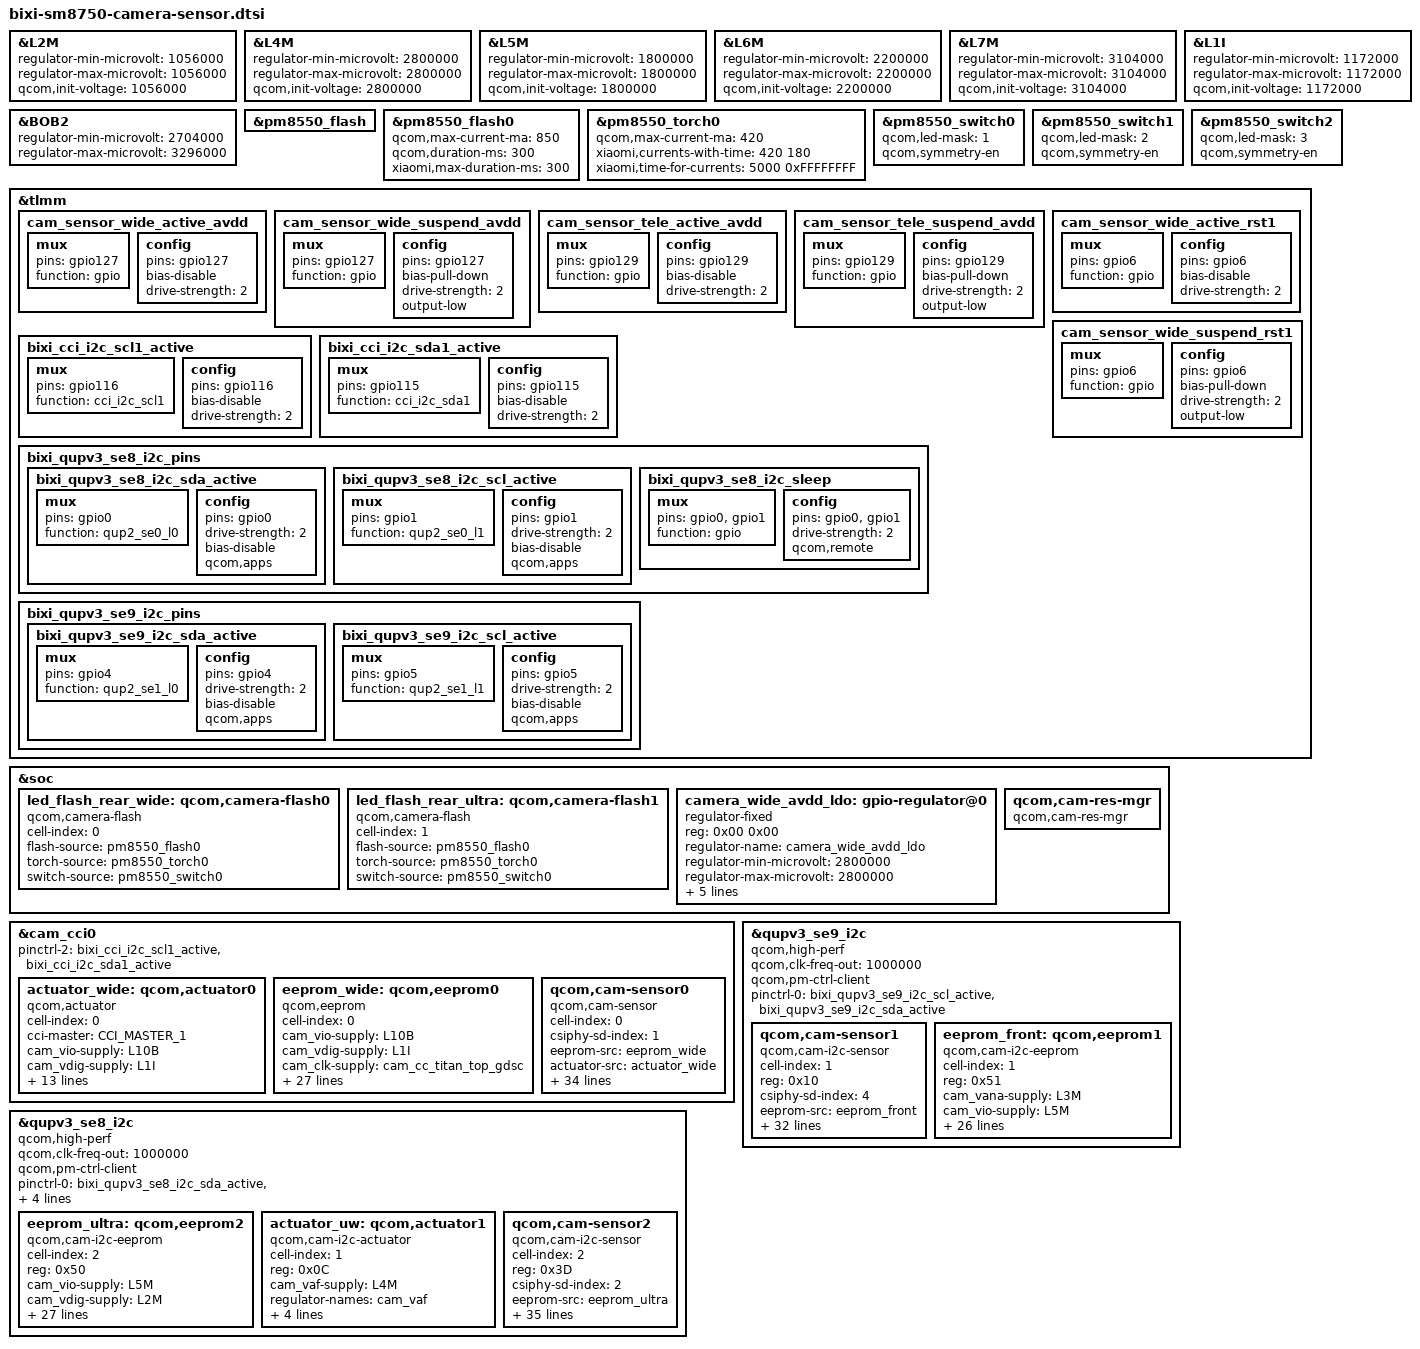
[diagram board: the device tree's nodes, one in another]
#include <dt-bindings/msm-camera.h>

&L2M {
	regulator-min-microvolt = <1056000>;
	regulator-max-microvolt = <1056000>;
	qcom,init-voltage = <1056000>;
};

&L4M {
	regulator-min-microvolt = <2800000>;
	regulator-max-microvolt = <2800000>;
	qcom,init-voltage = <2800000>;
};

&L5M {
	regulator-min-microvolt = <1800000>;
	regulator-max-microvolt = <1800000>;
	qcom,init-voltage = <1800000>;
};

&L6M {
	regulator-min-microvolt = <2200000>;
	regulator-max-microvolt = <2200000>;
	qcom,init-voltage = <2200000>;
};

&L7M {
	regulator-min-microvolt = <3104000>;
	regulator-max-microvolt = <3104000>;
	qcom,init-voltage = <3104000>;
};

&L1I {
	regulator-min-microvolt = <1172000>;
	regulator-max-microvolt = <1172000>;
	qcom,init-voltage = <1172000>;
};

&BOB2 {
	regulator-min-microvolt = <2704000>;
	regulator-max-microvolt = <3296000>;
};

&pm8550_flash {
	status = "ok";
};


&pm8550_flash0 {
	qcom,max-current-ma = <850>;
	qcom,duration-ms = <300>;
	xiaomi,max-duration-ms = <300>;
};

&pm8550_torch0{
	qcom,max-current-ma = <420>;
	xiaomi,currents-with-time = <420 180>;
	xiaomi,time-for-currents = <5000 0xFFFFFFFF>;  /* 0xFFFFFFFF means flash always on*/
};

&pm8550_switch0 {
	qcom,led-mask = <1>;
	qcom,symmetry-en;
};

&pm8550_switch1 {
	qcom,led-mask = <2>;
	qcom,symmetry-en;
};

&pm8550_switch2 {
	qcom,led-mask = <3>;
	qcom,symmetry-en;
};

&tlmm {
//wide avdd
	cam_sensor_wide_active_avdd: cam_sensor_wide_active_avdd {
		mux {
			pins = "gpio127";
			function = "gpio";
		};
		config {
			pins = "gpio127";
			bias-disable; /* No PULL */
			drive-strength = <2>; /* 2 MA */
		};
	};
	cam_sensor_wide_suspend_avdd: cam_sensor_wide_suspend_avdd {
		mux {
			pins = "gpio127";
			function = "gpio";
		};
		config {
			pins = "gpio127";
			bias-pull-down; /* PULL DOWN */
			drive-strength = <2>; /* 2 MA */
			output-low;
		};
	};

//tele avdd
	cam_sensor_tele_active_avdd: cam_sensor_tele_active_avdd {
		mux {
			pins = "gpio129";
			function = "gpio";
		};
		config {
			pins = "gpio129";
			bias-disable; /* No PULL */
			drive-strength = <2>; /* 2 MA */
		};
	};
	cam_sensor_tele_suspend_avdd: cam_sensor_tele_suspend_avdd {
		mux {
			pins = "gpio129";
			function = "gpio";
		};
		config {
			pins = "gpio129";
			bias-pull-down; /* PULL DOWN */
			drive-strength = <2>; /* 2 MA */
			output-low;
		};
	};

//Wide reset
	cam_sensor_wide_active_rst1: cam_sensor_wide_active_rst1 {
		mux {
			pins = "gpio6";
			function = "gpio";
		};

		config {
			pins = "gpio6";
			bias-disable; /* No PULL */
			drive-strength = <2>; /* 2 MA */
		};
	};

	cam_sensor_wide_suspend_rst1: cam_sensor_wide_suspend_rst1 {
		mux {
			pins = "gpio6";
			function = "gpio";
		};

		config {
			pins = "gpio6";
			bias-pull-down; /* PULL DOWN */
			drive-strength = <2>; /* 2 MA */
			output-low;
		};
	};

	bixi_cci_i2c_scl1_active: bixi_cci_i2c_scl1_active {
		mux {
			/* CLK, DATA */
			pins = "gpio116";
			function = "cci_i2c_scl1";
		};

		config {
			pins = "gpio116";
			bias-disable; /* NO PULL */
			drive-strength = <2>; /* 2 MA */
		};
	};

	bixi_cci_i2c_sda1_active: bixi_cci_i2c_sda1_active {
		mux {
			/* CLK, DATA */
			pins = "gpio115";
			function = "cci_i2c_sda1";
		};

		config {
			pins = "gpio115";
			bias-disable; /* NO PULL */
			drive-strength = <2>; /* 2 MA */
		};
	};

	bixi_qupv3_se8_i2c_pins: bixi_qupv3_se8_i2c_pins {
		bixi_qupv3_se8_i2c_sda_active: bixi_qupv3_se8_i2c_sda_active {
			mux {
				pins = "gpio0";
				function = "qup2_se0_l0";
			};

			config {
				pins = "gpio0";
				drive-strength = <2>;
				bias-disable;
				qcom,apps;
			};
		};

		bixi_qupv3_se8_i2c_scl_active: bixi_qupv3_se8_i2c_scl_active {
			mux {
				pins = "gpio1";
				function = "qup2_se0_l1";
			};

			config {
				pins = "gpio1";
				drive-strength = <2>;
				bias-disable;
				qcom,apps;
			};
		};

		bixi_qupv3_se8_i2c_sleep: bixi_qupv3_se8_i2c_sleep {
			mux {
				pins = "gpio0", "gpio1";
				function = "gpio";
			};

			config {
				pins = "gpio0", "gpio1";
				drive-strength = <2>;
				qcom,remote;
			};
		};
	};

	bixi_qupv3_se9_i2c_pins: bixi_qupv3_se9_i2c_pins {
		bixi_qupv3_se9_i2c_sda_active: bixi_qupv3_se9_i2c_sda_active {
			mux {
				pins = "gpio4";
				function = "qup2_se1_l0";
			};

			config {
				pins = "gpio4";
				drive-strength = <2>;
				bias-disable;
				qcom,apps;
			};
		};

	    bixi_qupv3_se9_i2c_scl_active: bixi_qupv3_se9_i2c_scl_active {
			mux {
				pins = "gpio5";
				function = "qup2_se1_l1";
			};

			config {
				pins = "gpio5";
				drive-strength = <2>;
				bias-disable;
				qcom,apps;
			};
		};
	};
};

&soc {

	led_flash_rear_wide: qcom,camera-flash0 {
		cell-index = <0>;
		compatible = "qcom,camera-flash";
		flash-source = <&pm8550_flash0>;
		torch-source = <&pm8550_torch0>;
		switch-source = <&pm8550_switch0>;
		status = "ok";
	};

	led_flash_rear_ultra: qcom,camera-flash1 {
		cell-index = <1>;
		compatible = "qcom,camera-flash";
		flash-source = <&pm8550_flash0>;
		torch-source = <&pm8550_torch0>;
		switch-source = <&pm8550_switch0>;
		status = "ok";
	};

//wide avdd
	camera_wide_avdd_ldo: gpio-regulator@0 {
		compatible = "regulator-fixed";
		reg = <0x00 0x00>;
		regulator-name = "camera_wide_avdd_ldo";
		regulator-min-microvolt = <2800000>;
		regulator-max-microvolt = <2800000>;
		regulator-enable-ramp-delay = <100>;
		enable-active-high;
		gpio = <&tlmm 127 0>;
		pinctrl-names = "wide_avdd_active", "wide_avdd_suspend";
		pinctrl-0 = <&cam_sensor_wide_active_avdd
					 &cam_sensor_wide_suspend_avdd>;
	};
	qcom,cam-res-mgr {
		compatible = "qcom,cam-res-mgr";
		status = "ok";
	};
};

&cam_cci0 {
	pinctrl-2 = <&bixi_cci_i2c_scl1_active &bixi_cci_i2c_sda1_active>;

	// wide actuator
	actuator_wide: qcom,actuator0 {
		cell-index = <0>;
		compatible = "qcom,actuator";
		cci-master = <CCI_MASTER_1>;
		cam_vio-supply = <&L10B>;
		cam_vdig-supply = <&L1I>;
		cam_clk-supply = <&cam_cc_titan_top_gdsc>;
		cam_vaf-supply = <&L7M>;
		cam_bob2-supply = <&BOB2>;
		cam_vana-supply = <&camera_wide_avdd_ldo>;
		regulator-names = "cam_vio", "cam_vdig", "cam_clk", "cam_vana", "cam_vaf", "cam_bob2";
		rgltr-cntrl-support;
		rgltr-min-voltage = <1800000 1172000 0 2800000 3104000 2704000>;
		rgltr-max-voltage = <1800000 1172000 0 2800000 3104000 3296000>;
		rgltr-load-current = <4000 913000 0 119000 150000 2000000>;
	};

	eeprom_wide: qcom,eeprom0 {
		cell-index = <0>;
		compatible = "qcom,eeprom";
		cam_vio-supply = <&L10B>;
		cam_vdig-supply = <&L1I>;
		cam_clk-supply = <&cam_cc_titan_top_gdsc>;
		cam_vaf-supply = <&L7M>;
		cam_bob2-supply = <&BOB2>;
		cam_vana-supply = <&camera_wide_avdd_ldo>;
		regulator-names = "cam_vio", "cam_vdig", "cam_clk", "cam_vana", "cam_vaf", "cam_bob2";
		rgltr-cntrl-support;
		rgltr-min-voltage = <1800000 1172000 0 2800000 3104000 2704000>;
		rgltr-max-voltage = <1800000 1172000 0 2800000 3104000 3296000>;
		rgltr-load-current = <4000 913000 0 119000 150000 2000000>;
		gpio-no-mux = <0>;
		pinctrl-names = "cam_default", "cam_suspend";
		pinctrl-0 = <&cam_sensor_mclk1_active
				 &cam_sensor_wide_active_rst1>;
		pinctrl-1 = <&cam_sensor_mclk1_suspend
				 &cam_sensor_wide_suspend_rst1>;
		gpios = <&tlmm 90 0>,
			<&tlmm 6 0>;
		gpio-reset = <1>;
		gpio-req-tbl-num = <0 1>;
		gpio-req-tbl-flags = <1 0>;
		gpio-req-tbl-label = "CAMIF_MCLK1",
					"CAM_RESET1";
		cci-master = <CCI_MASTER_1>;
		clocks = <&cambistmclkcc CAM_BIST_MCLK_CC_MCLK1_CLK>;
		clock-names = "cam_clk";
		clock-cntl-level = "nominal";
		clock-rates = <19200000>;
		status = "ok";
	};

    // wide ovx8000
	qcom,cam-sensor0 {
		cell-index = <0>;
		compatible = "qcom,cam-sensor";
		csiphy-sd-index = <1>;
		eeprom-src = <&eeprom_wide>;
		actuator-src = <&actuator_wide>;
		led-flash-src = <&led_flash_rear_wide>;
		sensor-position-roll = <90>;
		sensor-position-pitch = <0>;
		sensor-position-yaw = <180>;
		cam_vio-supply = <&L10B>;
		cam_vdig-supply = <&L1I>;
		cam_clk-supply = <&cam_cc_titan_top_gdsc>;
		cam_vaf-supply = <&L7M>;
		cam_bob2-supply = <&BOB2>;
		cam_vana-supply = <&camera_wide_avdd_ldo>;
		regulator-names = "cam_vio", "cam_vdig", "cam_clk", "cam_vana", "cam_vaf", "cam_bob2";
		rgltr-cntrl-support;
		rgltr-min-voltage = <1800000 1172000 0 2800000 3104000 2704000>;
		rgltr-max-voltage = <1800000 1172000 0 2800000 3104000 3296000>;
		rgltr-load-current = <4000 913000 0 119000 150000 2000000>;
		gpio-no-mux = <0>;
		pinctrl-names = "cam_default", "cam_suspend";
		pinctrl-0 = <&cam_sensor_mclk1_active
				 &cam_sensor_wide_active_rst1>;
		pinctrl-1 = <&cam_sensor_mclk1_suspend
				 &cam_sensor_wide_suspend_rst1>;
		gpios = <&tlmm 90 0>,
			<&tlmm 6 0>;
		gpio-reset = <1>;
		gpio-req-tbl-num = <0 1>;
		gpio-req-tbl-flags = <1 0>;
		gpio-req-tbl-label = "CAMIF_MCLK1",
					"CAM_RESET1";
		cci-master = <CCI_MASTER_1>;
		clocks = <&cambistmclkcc CAM_BIST_MCLK_CC_MCLK1_CLK>;
		clock-names = "cam_clk";
		clock-cntl-level = "nominal";
		clock-rates = <19200000>;
		status = "ok";
	};
};

&qupv3_se9_i2c {
	status = "ok";
	qcom,high-perf;
	qcom,clk-freq-out = <1000000>;
	qcom,pm-ctrl-client;
	pinctrl-0 = <&bixi_qupv3_se9_i2c_scl_active>, <&bixi_qupv3_se9_i2c_sda_active>;

	// Front Sensor
	qcom,cam-sensor1 {
		cell-index = <1>;
		reg = <0x10>;
		compatible = "qcom,cam-i2c-sensor";
		csiphy-sd-index = <4>;
		eeprom-src = <&eeprom_front>;
		sensor-position-roll = <270>;
		sensor-position-pitch = <0>;
		sensor-position-yaw = <0>;
		cam_vana-supply = <&L3M>;
		cam_vio-supply = <&L5M>;
		cam_vdig-supply = <&L1M>;
		cam_bob2-supply = <&BOB2>;
		cam_clk-supply = <&cam_cc_titan_top_gdsc>;
		regulator-names = "cam_vana", "cam_vio",
			"cam_vdig", "cam_clk", "cam_bob2";
		rgltr-cntrl-support;
		aon-camera-id = <AON_CAM1>;
		rgltr-min-voltage = <2800000 1800000 1104000 0 2704000>;
		rgltr-max-voltage = <2800000 1800000 1104000 0 3296000>;
		rgltr-load-current = <150000 150000 150000 0 2000000>;
		gpio-no-mux = <0>;
		pinctrl-names = "cam_default", "cam_suspend";
		pinctrl-0 = <&cam_sensor_mclk4_active
			&cam_sensor_active_rst4>;
		pinctrl-1 = <&cam_sensor_mclk4_suspend
			&cam_sensor_suspend_rst4>;
		gpios = <&tlmm 93 0>, <&tlmm 7 0>;
		gpio-reset = <1>;
		gpio-req-tbl-num = <0 1>;
		gpio-req-tbl-flags = <1 0>;
		gpio-req-tbl-label = "CAMIF_MCLK4", "CAM_RESET4";
		clocks = <&cambistmclkcc CAM_BIST_MCLK_CC_MCLK4_CLK>;
		clock-names = "cam_clk";
		clock-cntl-level = "nominal";
		clock-rates = <19200000>;
		status = "ok";
	};
	// Front eeprom
	eeprom_front: qcom,eeprom1 {
		cell-index = <1>;
		reg = <0x51>;
		compatible = "qcom,cam-i2c-eeprom";
		cam_vana-supply = <&L3M>;
		cam_vio-supply = <&L5M>;
		cam_vdig-supply = <&L1M>;
		cam_bob2-supply = <&BOB2>;
		cam_clk-supply = <&cam_cc_titan_top_gdsc>;
		regulator-names = "cam_vana", "cam_vio",
			"cam_vdig", "cam_clk", "cam_bob2";
		rgltr-cntrl-support;
		rgltr-min-voltage = <2800000 1800000 1104000 0 2704000>;
		rgltr-max-voltage = <2800000 1800000 1104000 0 3296000>;
		rgltr-load-current = <150000 150000 150000 0 2000000>;
		gpio-no-mux = <0>;
		pinctrl-names = "cam_default", "cam_suspend";
		pinctrl-0 = <&cam_sensor_mclk4_active
			&cam_sensor_active_rst4>;
		pinctrl-1 = <&cam_sensor_mclk4_suspend
			&cam_sensor_suspend_rst4>;
		gpios = <&tlmm 93 0>, <&tlmm 7 0>;
		gpio-reset = <1>;
		gpio-req-tbl-num = <0 1>;
		gpio-req-tbl-flags = <1 0>;
		gpio-req-tbl-label = "CAMIF_MCLK4", "CAM_RESET4";
		clocks = <&cambistmclkcc CAM_BIST_MCLK_CC_MCLK4_CLK>;
		clock-names = "cam_clk";
		clock-cntl-level = "nominal";
		clock-rates = <19200000>;
		status = "ok";
	};
};

&qupv3_se8_i2c {
	status = "ok";
	qcom,high-perf;
	qcom,clk-freq-out = <1000000>;
	qcom,pm-ctrl-client;
	pinctrl-0 = <&bixi_qupv3_se8_i2c_sda_active>, <&bixi_qupv3_se8_i2c_scl_active>;
	pinctrl-1 = <&bixi_qupv3_se8_i2c_sleep>;
	dmas = <&gpi_dma2 0 0 3 1024 0>,
		<&gpi_dma2 1 0 3 1024 0>;

	// ultra eeprom
	eeprom_ultra: qcom,eeprom2 {
		cell-index = <2>;
		reg = <0x50>;
		compatible = "qcom,cam-i2c-eeprom";
		cam_vio-supply = <&L5M>;
		cam_vdig-supply = <&L2M>;
		cam_clk-supply = <&cam_cc_titan_top_gdsc>;
		cam_vana-supply = <&L6M>;
		cam_bob2-supply = <&BOB2>;
		cam_vaf-supply = <&L4M>;
		regulator-names = "cam_vio", "cam_vdig","cam_clk", "cam_vana", "cam_bob2", "cam_vaf";
		rgltr-cntrl-support;
		rgltr-min-voltage = <1800000 1056000 0 2200000 2704000 2800000>;
		rgltr-max-voltage = <1800000 1056000 0 2200000 3296000 2800000>;
		rgltr-load-current = <150000 150000 0  150000 2000000 103000>;
		gpio-no-mux = <0>;
		pinctrl-names = "cam_default", "cam_suspend";
		pinctrl-0 = <&cam_sensor_mclk2_active
					&cam_sensor_active_rst2>;
		pinctrl-1 = <&cam_sensor_mclk2_suspend
					&cam_sensor_suspend_rst2>;
		gpios = <&tlmm 91 0>, <&tlmm 3 0>;
		gpio-reset = <1>;
		gpio-req-tbl-num = <0 1>;
		gpio-req-tbl-flags = <1 0>;
		gpio-req-tbl-label = "CAMUW_MCLK2", "CAMUW_RESET2";
		clocks = <&cambistmclkcc CAM_BIST_MCLK_CC_MCLK2_CLK>;
		clock-names = "cam_clk";
		clock-cntl-level = "nominal";
		clock-rates = <19200000>;
		status = "ok";
	};

	actuator_uw: qcom,actuator1 {
		cell-index = <1>;
		reg = <0x0C>;
		compatible = "qcom,cam-i2c-actuator";
		cam_vaf-supply = <&L4M>;
		regulator-names = "cam_vaf";
		rgltr-cntrl-support;
		rgltr-min-voltage = <2800000>;
		rgltr-max-voltage = <2800000>;
		rgltr-load-current = <103000>;
		status = "ok";
	};

	// uw sensor
	qcom,cam-sensor2 {
		cell-index = <2>;
		reg = <0x3D>;
		compatible = "qcom,cam-i2c-sensor";
		csiphy-sd-index = <2>;
		eeprom-src  = <&eeprom_ultra>;
		actuator-src = <&actuator_uw>;
		led-flash-src = <&led_flash_rear_ultra>;
		sensor-position-roll = <90>;
		sensor-position-pitch = <0>;
		sensor-position-yaw = <180>;
		cam_vio-supply = <&L5M>;
		cam_vdig-supply = <&L2M>;
		cam_clk-supply = <&cam_cc_titan_top_gdsc>;
		cam_vana-supply = <&L6M>;
		cam_bob2-supply = <&BOB2>;
		cam_vaf-supply = <&L4M>;
		regulator-names = "cam_vio", "cam_vdig","cam_clk", "cam_vana", "cam_bob2", "cam_vaf";
		rgltr-cntrl-support;
		aon-camera-id = <AON_CAM2>;
		rgltr-min-voltage = <1800000 1056000 0 2200000 2704000 2800000>;
		rgltr-max-voltage = <1800000 1056000 0 2200000 3296000 2800000>;
		rgltr-load-current = <150000 150000 0  150000 2000000 103000>;
		gpio-no-mux = <0>;
		pinctrl-names = "cam_default", "cam_suspend";
		pinctrl-0 = <&cam_sensor_mclk2_active
					&cam_sensor_active_rst2>;
		pinctrl-1 = <&cam_sensor_mclk2_suspend
					&cam_sensor_suspend_rst2>;
		gpios = <&tlmm 91 0>, <&tlmm 3 0>;
		gpio-reset = <1>;
		gpio-req-tbl-num = <0 1>;
		gpio-req-tbl-flags = <1 0>;
		gpio-req-tbl-label = "CAMUW_MCLK2", "CAMUW_RESET2";
		clocks = <&cambistmclkcc CAM_BIST_MCLK_CC_MCLK2_CLK>;
		clock-names = "cam_clk";
		clock-cntl-level = "nominal";
		clock-rates = <19200000>;
		status = "ok";
	};
};
